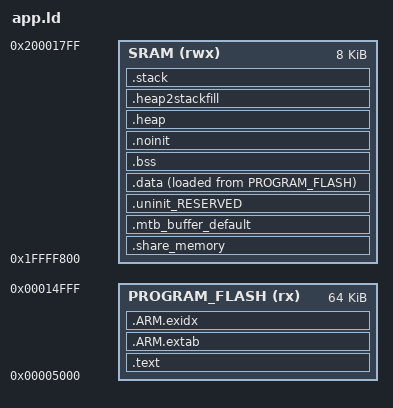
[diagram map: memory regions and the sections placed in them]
GROUP (
  "libcr_nohost_nf.a"
  "libcr_c.a"
  "libcr_eabihelpers.a"
  "libgcc.a"
)


MEMORY
{
  /* Define each memory region */
  PROGRAM_FLASH (rx) : ORIGIN = 0x5000, LENGTH = 0x10000 /* 64K bytes (alias Flash) */  
  SRAM (rwx) : ORIGIN = 0x1ffff800, LENGTH = 0x2000 /* 8K bytes (alias RAM) */  
}

  /* Define a symbol for the top of each memory region */
  __base_PROGRAM_FLASH = 0x0  ; /* PROGRAM_FLASH */  
  __base_Flash = 0x0 ; /* Flash */  
  __top_PROGRAM_FLASH = 0x0 + 0x10000 ; /* 64K bytes */  
  __top_Flash = 0x0 + 0x10000 ; /* 64K bytes */  
  __base_SRAM = 0x1ffff800  ; /* SRAM */  
  __base_RAM = 0x1ffff800 ; /* RAM */  
  __top_SRAM = 0x1ffff800 + 0x2000 ; /* 8K bytes */  
  __top_RAM = 0x1ffff800 + 0x2000 ; /* 8K bytes */  


ENTRY(ResetISR)

SECTIONS
{
	
    /* Shared Memory Section */
    .share_memory (NOLOAD) : ALIGN(4)
    {
        __share_memory_start__ = .; /* Start address of the shared memory */
        KEEP(*(.share_memory*));    /* Keep all symbols in .share_memory */
        . = ALIGN(4);
        __share_memory_end__ = .;   /* End address of the shared memory */
    } > SRAM
    
    
     /* MAIN TEXT SECTION */
    .text : ALIGN(4)
    {
        FILL(0xff)
        __vectors_start__ = ABSOLUTE(.) ;
        KEEP(*(.isr_vector))
        /* Global Section Table */
        . = ALIGN(4) ;
        __section_table_start = .;
        __data_section_table = .;
        LONG(LOADADDR(.data));
        LONG(    ADDR(.data));
        LONG(  SIZEOF(.data));
        __data_section_table_end = .;
        __bss_section_table = .;
        LONG(    ADDR(.bss));
        LONG(  SIZEOF(.bss));
        __bss_section_table_end = .;
        __section_table_end = . ;
        /* End of Global Section Table */

        *(.after_vectors*)


        
       *(.text*)
       *(.rodata .rodata.* .constdata .constdata.*)
       . = ALIGN(4);
    } > PROGRAM_FLASH
    /*
     * for exception handling/unwind - some Newlib functions (in common
     * with C++ and STDC++) use this.
     */
    .ARM.extab : ALIGN(4)
    {
        *(.ARM.extab* .gnu.linkonce.armextab.*)
    } > PROGRAM_FLASH

    .ARM.exidx : ALIGN(4)
    {
        __exidx_start = .;
        *(.ARM.exidx* .gnu.linkonce.armexidx.*)
        __exidx_end = .;
    } > PROGRAM_FLASH
 
    _etext = .;
        
    /* MAIN DATA SECTION */
    /* Default MTB section */
    .mtb_buffer_default (NOLOAD) :
    {
        KEEP(*(.mtb*))
    } > SRAM AT > SRAM
    .uninit_RESERVED (NOLOAD) : ALIGN(4)
    {
        _start_uninit_RESERVED = .;
        KEEP(*(.bss.$RESERVED*))
       . = ALIGN(4) ;
        _end_uninit_RESERVED = .;
    } > SRAM AT> SRAM

    /* Main DATA section (SRAM) */
    .data : ALIGN(4)
    {
       FILL(0xff)
       _data = . ;
       PROVIDE(__start_data_RAM = .) ;
       PROVIDE(__start_data_SRAM = .) ;
       *(vtable)
       *(.ramfunc*)
       KEEP(*(CodeQuickAccess))
       KEEP(*(DataQuickAccess))
       *(RamFunction)
       *(.data*)
       . = ALIGN(4) ;
       _edata = . ;
       PROVIDE(__end_data_RAM = .) ;
       PROVIDE(__end_data_SRAM = .) ;
    } > SRAM AT>PROGRAM_FLASH

    /* MAIN BSS SECTION */
    .bss (NOLOAD) : ALIGN(4)
    {
        _bss = .;
        PROVIDE(__start_bss_RAM = .) ;
        PROVIDE(__start_bss_SRAM = .) ;
        *(.bss*)
        *(COMMON)
        . = ALIGN(4) ;
        _ebss = .;
        PROVIDE(__end_bss_RAM = .) ;
        PROVIDE(__end_bss_SRAM = .) ;
        PROVIDE(end = .);
    } > SRAM AT> SRAM



    /* DEFAULT NOINIT SECTION */
    .noinit (NOLOAD): ALIGN(4)
    {
        _noinit = .;
        PROVIDE(__start_noinit_RAM = .) ;
        PROVIDE(__start_noinit_SRAM = .) ;
        *(.noinit*)
         . = ALIGN(4) ;
        _end_noinit = .;
       PROVIDE(__end_noinit_RAM = .) ;
       PROVIDE(__end_noinit_SRAM = .) ;        
    } > SRAM AT> SRAM

    /* Reserve and place Heap within memory map */
    _HeapSize = 0x200;
    .heap (NOLOAD) :  ALIGN(4)
    {
        _pvHeapStart = .;
        . += _HeapSize;
        . = ALIGN(4);
        _pvHeapLimit = .;
    } > SRAM

     _StackSize = 0x200;
     /* Reserve space in memory for Stack */
    .heap2stackfill (NOLOAD) :
    {
        . += _StackSize;
    } > SRAM
    /* Locate actual Stack in memory map */
    .stack ORIGIN(SRAM) + LENGTH(SRAM) - _StackSize - 0 (NOLOAD) :  ALIGN(4)
    {
        _vStackBase = .;
        . = ALIGN(4);
        _vStackTop = . + _StackSize;
    } > SRAM

    /* Provide basic symbols giving location and size of main text
     * block, including initial values of RW data sections. Note that
     * these will need extending to give a complete picture with
     * complex images (e.g multiple Flash banks).
     */
    _image_start = LOADADDR(.text);
    _image_end = LOADADDR(.data) + SIZEOF(.data);
    _image_size = _image_end - _image_start;
}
